AUTOSAR XML (schema 314)
package /ComponentType
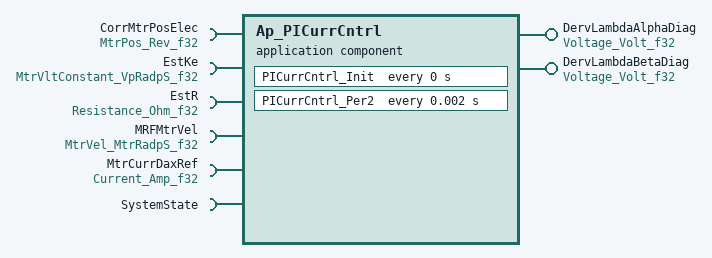
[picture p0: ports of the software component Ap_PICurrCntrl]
  application software component type Ap_PICurrCntrl
    provide port DervLambdaAlphaDiag: unqueued-sender-com-spec{data-element=Volt_f32, can-invalidate=false, init-value=D_ZERO_ULS_F32}, provided-interface=Voltage_Volt_f32
    provide port DervLambdaBetaDiag: unqueued-sender-com-spec{data-element=Volt_f32, can-invalidate=false, init-value=D_ZERO_ULS_F32}, provided-interface=Voltage_Volt_f32
    6 x require port:
      CorrMtrPosElec: unqueued-receiver-com-spec{data-element=Rev_f32, init-value=D_ZERO_ULS_F32}, required-interface=MtrPos_Rev_f32
      EstKe: unqueued-receiver-com-spec{data-element=VpRadpS_f32, init-value=D_ZERO_ULS_F32}, required-interface=MtrVltConstant_VpRadpS_f32
      EstR: unqueued-receiver-com-spec{data-element=Ohm_f32, init-value=D_ZERO_ULS_F32}, required-interface=Resistance_Ohm_f32
      MRFMtrVel: unqueued-receiver-com-spec{data-element=MtrRadpS_f32, init-value=D_ZERO_ULS_F32}, required-interface=MtrVel_MtrRadpS_f32
      MtrCurrDaxRef: unqueued-receiver-com-spec{data-element=Amp_f32, init-value=D_ZERO_ULS_F32}, required-interface=Current_Amp_f32
      SystemState: required-interface=SystemState
  internal behavior Ap_PICurrCntrl_InternalBehavior: component=Ap_PICurrCntrl
    timing event PICurrCntrl_InitEvent: start-on-event=PICurrCntrl_Init, period=0
    timing event TMT_PICurrCntrl_Per2: start-on-event=PICurrCntrl_Per2, period=0.002
    port-api-options:
      enable-take-address=false, indirect-api=false, port=CorrMtrPosElec
      enable-take-address=false, indirect-api=false, port=DervLambdaAlphaDiag
      enable-take-address=false, indirect-api=false, port=DervLambdaBetaDiag
      enable-take-address=false, indirect-api=false, port=EstKe
      enable-take-address=false, indirect-api=false, port=EstR
      enable-take-address=false, indirect-api=false, port=MRFMtrVel
      enable-take-address=false, indirect-api=false, port=MtrCurrDaxRef
      enable-take-address=false, indirect-api=false, port=SystemState
    runnable PICurrCntrl_Init
    runnable PICurrCntrl_Per2
      5 x data read access:
        READ_CorrMtrPosElec_Rev_f32: data-element=CorrMtrPosElec.Rev_f32
        READ_EstKe_VpRadpS_f32: data-element=EstKe.VpRadpS_f32
        READ_EstR_Ohm_f32: data-element=EstR.Ohm_f32
        READ_MRFMtrVel_MtrRadpS_f32: data-element=MRFMtrVel.MtrRadpS_f32
        READ_MtrCurrDaxRef_Amp_f32: data-element=MtrCurrDaxRef.Amp_f32
      data write access WRITE_DervLambdaAlphaDiag_Volt_f32: data-element=DervLambdaAlphaDiag.Volt_f32
      data write access WRITE_DervLambdaBetaDiag_Volt_f32: data-element=DervLambdaBetaDiag.Volt_f32
  swc implementation Ap_PICurrCntrl_Implementation: behavior=Ap_PICurrCntrl_InternalBehavior
    code-descriptors:
      code Code: type=SRC
